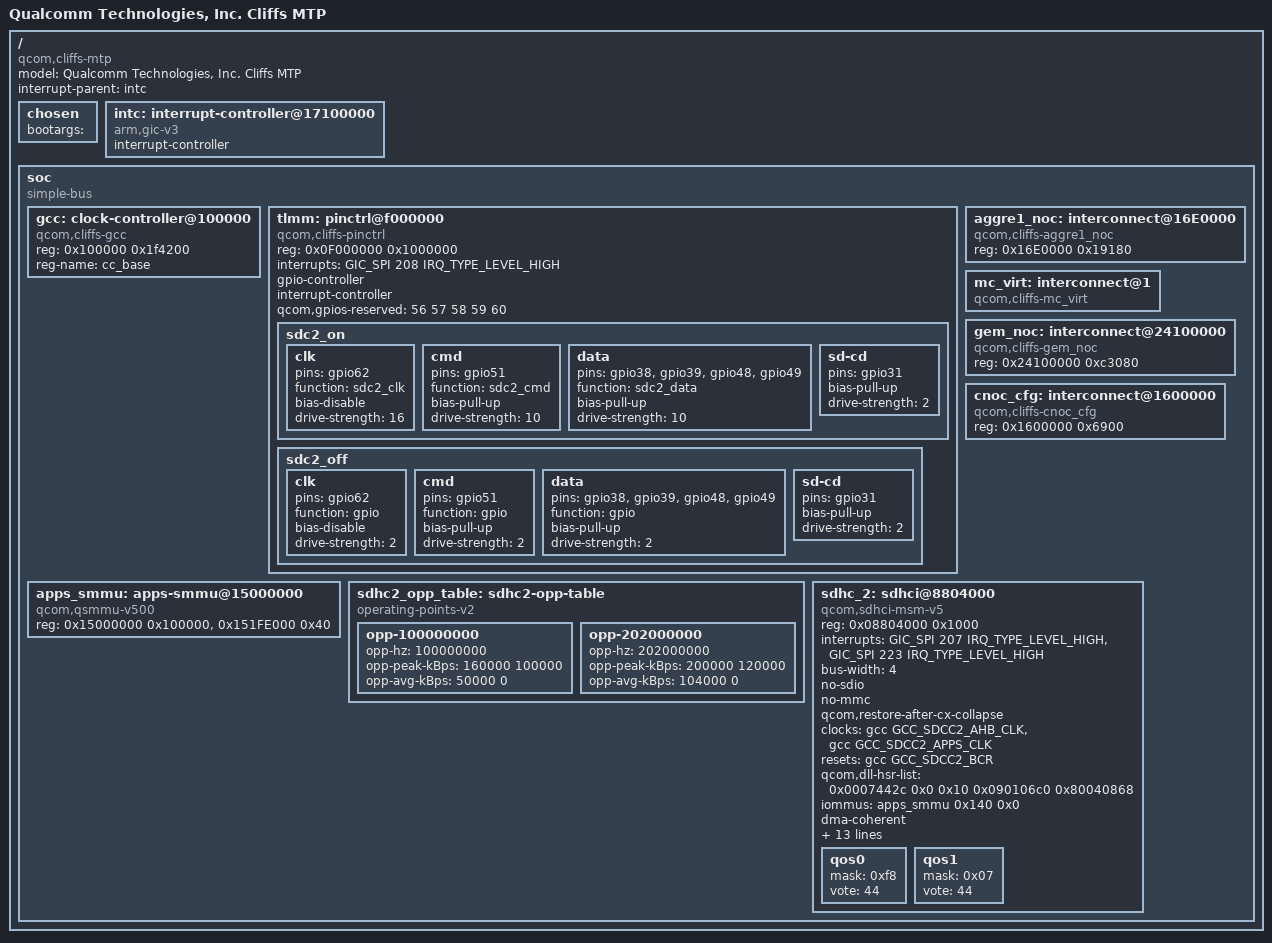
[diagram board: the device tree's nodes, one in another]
/*
 * Retroid Pocket G2 - Qualcomm G2 Gen 2 / Cliffs SD-only target
 *
 * Phase B: first compile-verified G2 SD-only DTS artifact, integrated into
 * the Linux 7.1.5 kernel DT build as a real arch/arm64/boot/dts/qcom target
 * (see scripts/build-g2-kernel.sh and kernel/g2/kernel.conf). This file is
 * copied into the kernel tree at arch/arm64/boot/dts/qcom/g2-cliffs-sd.dts
 * and built by the kernel's own DT build system (cpp + dtc via Kbuild).
 *
 * SOURCE RULES
 *  - Every value below is either captured from the physical G2 Android DT
 *    (see dumps/g2/g2_sdhci_dt_dump.txt and dumps/g2/*.txt) or taken from
 *    the exact Cliffs Linux source family referenced by the project:
 *      * LineageOS android_kernel_qcom_sm8650-devicetrees commit
 *        4e146886d41b4de80f17ae1f5e19ed0839012136 (qcom/cliffs.dtsi,
 *        qcom/cliffs-mtp.dtsi, qcom/cliffs-pinctrl.dtsi)
 *      * OnePlusOSS android_kernel_oneplus_sm8650 commit
 *        e39bf7032e38c547d588372a11a5dd55eb714860
 *        (include/dt-bindings/clock/qcom,gcc-cliffs.h,
 *         include/dt-bindings/interconnect/qcom,cliffs.h)
 *  - No value is guessed. Values not yet source-verified are left as
 *    explicit UNRESOLVED/TODO entries and are commented out so this file
 *    still compiles as a useful target.
 *  - The dt-bindings constants below are defined locally because Linux
 *    7.1.5 does NOT ship qcom,gcc-cliffs.h / qcom,cliffs.h headers. The
 *    numeric values are source-verified against the Cliffs bindings above;
 *    they are not inferred from SM8550/SM8650.
 *
 * SAFETY GATE
 *  - This DTS/DTSI produces a compile-verified DTB only. Compiling it does
 *    NOT make the G2 bootable and does NOT modify any device storage.
 *  - microSD-only: this target exists solely for the removable-SD bring-up
 *    path. Internal Android/UFS/ABL/vbmeta/dtbo storage is never touched.
 */

/dts-v1/;

/* Local macro definitions - resolve to values in dt-bindings headers. */
#define GIC_SPI 0
#define IRQ_TYPE_LEVEL_HIGH 4
#define GPIO_ACTIVE_LOW 1
/* Cliff binding IDs, source-verified from qcom,gcc-cliffs.h / qcom,cliffs.h */
#define GCC_SDCC2_AHB_CLK 108
#define GCC_SDCC2_APPS_CLK 109
#define GCC_SDCC2_BCR 17
#define MASTER_SDCC_2 47
#define SLAVE_EBI1 512
#define MASTER_APPSS_PROC 2
#define SLAVE_SDCC_2 542

/ {
	model = "Qualcomm Technologies, Inc. Cliffs MTP";
	compatible = "qcom,cliffs-mtp", "qcom,cliffs", "qcom,cliffsp-mtp",
		     "qcom,cliffsp", "qcom,mtp";

	#address-cells = <2>;
	#size-cells = <2>;
	interrupt-parent = <&intc>;

	chosen: chosen {
		bootargs = "";
	};

	intc: interrupt-controller@17100000 {
		compatible = "arm,gic-v3";
		#interrupt-cells = <3>;
		interrupt-controller;
		#address-cells = <2>;
		#size-cells = <2>;
		ranges;
	};

	soc: soc {
		#address-cells = <1>;
		#size-cells = <1>;
		ranges = <0 0 0 0xffffffff>;
		compatible = "simple-bus";

		gcc: clock-controller@100000 {
			compatible = "qcom,cliffs-gcc", "syscon";
			reg = <0x100000 0x1f4200>;
			reg-name = "cc_base";
			#clock-cells = <1>;
			#reset-cells = <1>;
		};

		tlmm: pinctrl@f000000 {
			compatible = "qcom,cliffs-pinctrl";
			reg = <0x0F000000 0x1000000>;
			interrupts = <GIC_SPI 208 IRQ_TYPE_LEVEL_HIGH>;
			gpio-controller;
			#gpio-cells = <2>;
			interrupt-controller;
			#interrupt-cells = <2>;
			qcom,gpios-reserved = <56 57 58 59 60>;

			sdc2_on: sdc2_on {
				clk {
					pins = "gpio62";
					function = "sdc2_clk";
					bias-disable;
					drive-strength = <16>;
				};

				cmd {
					pins = "gpio51";
					function = "sdc2_cmd";
					bias-pull-up;
					drive-strength = <10>;
				};

				data {
					pins = "gpio38", "gpio39", "gpio48", "gpio49";
					function = "sdc2_data";
					bias-pull-up;
					drive-strength = <10>;
				};

				sd-cd {
					pins = "gpio31";
					bias-pull-up;
					drive-strength = <2>;
				};
			};

			sdc2_off: sdc2_off {
				clk {
					pins = "gpio62";
					function = "gpio";
					bias-disable;
					drive-strength = <2>;
				};

				cmd {
					pins = "gpio51";
					function = "gpio";
					bias-pull-up;
					drive-strength = <2>;
				};

				data {
					pins = "gpio38", "gpio39", "gpio48", "gpio49";
					function = "gpio";
					bias-pull-up;
					drive-strength = <2>;
				};

				sd-cd {
					pins = "gpio31";
					bias-pull-up;
					drive-strength = <2>;
				};
			};
		};

		apps_smmu: apps-smmu@15000000 {
			compatible = "qcom,qsmmu-v500";
			reg = <0x15000000 0x100000>,
			      <0x151FE000 0x40>;
			reg-names = "base", "tcu-base";
			#iommu-cells = <2>;
		};

		aggre1_noc: interconnect@16E0000 {
			compatible = "qcom,cliffs-aggre1_noc";
			reg = <0x16E0000 0x19180>;
			#interconnect-cells = <1>;
		};

		mc_virt: interconnect@1 {
			compatible = "qcom,cliffs-mc_virt";
			#interconnect-cells = <1>;
		};

		gem_noc: interconnect@24100000 {
			compatible = "qcom,cliffs-gem_noc";
			reg = <0x24100000 0xc3080>;
			#interconnect-cells = <1>;
		};

		cnoc_cfg: interconnect@1600000 {
			compatible = "qcom,cliffs-cnoc_cfg";
			reg = <0x1600000 0x6900>;
			#interconnect-cells = <1>;
		};

		sdhc2_opp_table: sdhc2-opp-table {
			compatible = "operating-points-v2";

			opp-100000000 {
				opp-hz = /bits/ 64 <100000000>;
				opp-peak-kBps = <160000 100000>;
				opp-avg-kBps = <50000 0>;
			};

			opp-202000000 {
				opp-hz = /bits/ 64 <202000000>;
				opp-peak-kBps = <200000 120000>;
				opp-avg-kBps = <104000 0>;
			};
		};

		sdhc_2: sdhci@8804000 {
			status = "okay";

			compatible = "qcom,sdhci-msm-v5";
			reg = <0x08804000 0x1000>;
			reg-names = "hc";

			interrupts = <GIC_SPI 207 IRQ_TYPE_LEVEL_HIGH>,
				     <GIC_SPI 223 IRQ_TYPE_LEVEL_HIGH>;
			interrupt-names = "hc_irq", "pwr_irq";

			bus-width = <4>;
			no-sdio;
			no-mmc;

			qcom,restore-after-cx-collapse;

			/* G2 SDCC2 clocks - GCC_SDCC2_AHB_CLK / GCC_SDCC2_APPS_CLK */
			clocks = <&gcc GCC_SDCC2_AHB_CLK>,
				 <&gcc GCC_SDCC2_APPS_CLK>;
			clock-names = "iface", "core";

			/* G2 SDCC2 reset - GCC_SDCC2_BCR */
			resets = <&gcc GCC_SDCC2_BCR>;
			reset-names = "core_reset";

			qcom,dll-hsr-list = <0x0007442c 0x0 0x10
					     0x090106c0 0x80040868>;

			/* G2 Apps-SMMU stream 0x140 */
			iommus = <&apps_smmu 0x140 0x0>;
			dma-coherent;
			qcom,iommu-dma = "fastmap";
			qcom,iommu-dma-addr-pool = <0x40000000 0x10000000>;
			qcom,iommu-geometry = <0x40000000 0x10000000>;

			interconnects = <&aggre1_noc MASTER_SDCC_2 &mc_virt SLAVE_EBI1>,
					<&gem_noc MASTER_APPSS_PROC &cnoc_cfg SLAVE_SDCC_2>;
			interconnect-names = "sdhc-ddr", "cpu-sdhc";

			operating-points-v2 = <&sdhc2_opp_table>;

			pinctrl-names = "default", "sleep";
			pinctrl-0 = <&sdc2_on>;
			pinctrl-1 = <&sdc2_off>;

			/* G2 SD detect: Cliffs pinctrl GPIO31, active-low */
			cd-gpios = <&tlmm 31 GPIO_ACTIVE_LOW>;
			cd-debounce-delay-ms = <1500>;

			/*
			 * UNRESOLVED (TODO): Linux PMXR2230 regulator phandles.
			 * G2 physical DT resolves vdd-supply to
			 *   rpmh-regulator-ldob13 / regulator-pmxr2230-l13
			 * and vdd-io-supply to
			 *   rpmh-regulator-ldob23 / regulator-pmxr2230-l23.
			 * The exact Linux-side regulator node/labels in the
			 * selected kernel tree are NOT yet verified, so the
			 * supplies are intentionally omitted rather than guessed.
			 * vdd-supply = <&L13B>;
			 * vdd-io-supply = <&L23B>;
			 */

			qos0 {
				mask = <0xf8>;
				vote = <44>;
			};

			qos1 {
				mask = <0x07>;
				vote = <44>;
			};
		};
	};
};
